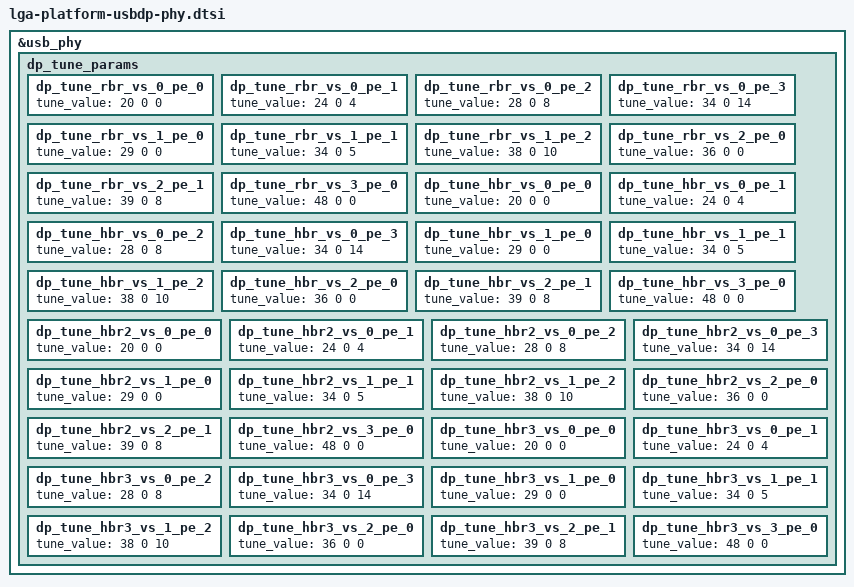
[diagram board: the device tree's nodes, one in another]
// SPDX-License-Identifier: GPL-2.0-only
/*
 * LGA platform USBDP PHY Tuning Values
 *
 * Copyright 2025 Google LLC.
 *
 */

&usb_phy {
	dp_tune_params {
		dp_tune_rbr_vs_0_pe_0 {
			tune_value = <20 0 0>;
		};
		dp_tune_rbr_vs_0_pe_1 {
			tune_value = <24 0 4>;
		};
		dp_tune_rbr_vs_0_pe_2 {
			tune_value = <28 0 8>;
		};
		dp_tune_rbr_vs_0_pe_3 {
			tune_value = <34 0 14>;
		};
		dp_tune_rbr_vs_1_pe_0 {
			tune_value = <29 0 0>;
		};
		dp_tune_rbr_vs_1_pe_1 {
			tune_value = <34 0 5>;
		};
		dp_tune_rbr_vs_1_pe_2 {
			tune_value = <38 0 10>;
		};
		dp_tune_rbr_vs_2_pe_0 {
			tune_value = <36 0 0>;
		};
		dp_tune_rbr_vs_2_pe_1 {
			tune_value = <39 0 8>;
		};
		dp_tune_rbr_vs_3_pe_0 {
			tune_value = <48 0 0>;
		};
		dp_tune_hbr_vs_0_pe_0 {
			tune_value = <20 0 0>;
		};
		dp_tune_hbr_vs_0_pe_1 {
			tune_value = <24 0 4>;
		};
		dp_tune_hbr_vs_0_pe_2 {
			tune_value = <28 0 8>;
		};
		dp_tune_hbr_vs_0_pe_3 {
			tune_value = <34 0 14>;
		};
		dp_tune_hbr_vs_1_pe_0 {
			tune_value = <29 0 0>;
		};
		dp_tune_hbr_vs_1_pe_1 {
			tune_value = <34 0 5>;
		};
		dp_tune_hbr_vs_1_pe_2 {
			tune_value = <38 0 10>;
		};
		dp_tune_hbr_vs_2_pe_0 {
			tune_value = <36 0 0>;
		};
		dp_tune_hbr_vs_2_pe_1 {
			tune_value = <39 0 8>;
		};
		dp_tune_hbr_vs_3_pe_0 {
			tune_value = <48 0 0>;
		};
		dp_tune_hbr2_vs_0_pe_0 {
			tune_value = <20 0 0>;
		};
		dp_tune_hbr2_vs_0_pe_1 {
			tune_value = <24 0 4>;
		};
		dp_tune_hbr2_vs_0_pe_2 {
			tune_value = <28 0 8>;
		};
		dp_tune_hbr2_vs_0_pe_3 {
			tune_value = <34 0 14>;
		};
		dp_tune_hbr2_vs_1_pe_0 {
			tune_value = <29 0 0>;
		};
		dp_tune_hbr2_vs_1_pe_1 {
			tune_value = <34 0 5>;
		};
		dp_tune_hbr2_vs_1_pe_2 {
			tune_value = <38 0 10>;
		};
		dp_tune_hbr2_vs_2_pe_0 {
			tune_value = <36 0 0>;
		};
		dp_tune_hbr2_vs_2_pe_1 {
			tune_value = <39 0 8>;
		};
		dp_tune_hbr2_vs_3_pe_0 {
			tune_value = <48 0 0>;
		};
		dp_tune_hbr3_vs_0_pe_0 {
			tune_value = <20 0 0>;
		};
		dp_tune_hbr3_vs_0_pe_1 {
			tune_value = <24 0 4>;
		};
		dp_tune_hbr3_vs_0_pe_2 {
			tune_value = <28 0 8>;
		};
		dp_tune_hbr3_vs_0_pe_3 {
			tune_value = <34 0 14>;
		};
		dp_tune_hbr3_vs_1_pe_0 {
			tune_value = <29 0 0>;
		};
		dp_tune_hbr3_vs_1_pe_1 {
			tune_value = <34 0 5>;
		};
		dp_tune_hbr3_vs_1_pe_2 {
			tune_value = <38 0 10>;
		};
		dp_tune_hbr3_vs_2_pe_0 {
			tune_value = <36 0 0>;
		};
		dp_tune_hbr3_vs_2_pe_1 {
			tune_value = <39 0 8>;
		};
		dp_tune_hbr3_vs_3_pe_0 {
			tune_value = <48 0 0>;
		};
	};
};
